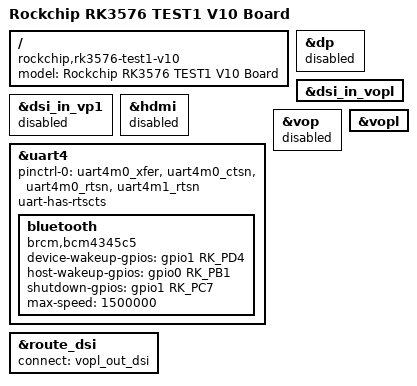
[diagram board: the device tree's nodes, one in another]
// SPDX-License-Identifier: (GPL-2.0+ OR MIT)
/*
 * Copyright (c) 2024 Rockchip Electronics Co., Ltd.
 *
 */

/dts-v1/;

#include "rk3576.dtsi"
#include "rk3576-test1.dtsi"
#include "rk3576-linux.dtsi"

/ {
	model = "Rockchip RK3576 TEST1 V10 Board";
	compatible = "rockchip,rk3576-test1-v10", "rockchip,rk3576";
};

&dp {
	status = "disabled";
};

&dsi_in_vopl {
	status = "okay";
};

&dsi_in_vp1 {
	status = "disabled";
};

&hdmi {
	status = "disabled";
};

&uart4 {
	status = "okay";
	pinctrl-names = "default";
	pinctrl-0 = <&uart4m0_xfer &uart4m0_ctsn &uart4m0_rtsn &uart4m1_rtsn>;
	uart-has-rtscts;

	bluetooth {
		compatible = "brcm,bcm4345c5";

		device-wakeup-gpios = <&gpio1 RK_PD4 GPIO_ACTIVE_HIGH>;
		host-wakeup-gpios = <&gpio0 RK_PB1 GPIO_ACTIVE_HIGH>;
		shutdown-gpios = <&gpio1 RK_PC7 GPIO_ACTIVE_HIGH>;
		max-speed = <1500000>;
	};
};

&vop {
	status = "disabled";
};

&vopl {
	status = "okay";
};

&route_dsi {
	status = "okay";
	connect = <&vopl_out_dsi>;
};

/delete-node/ &wireless_bluetooth;
